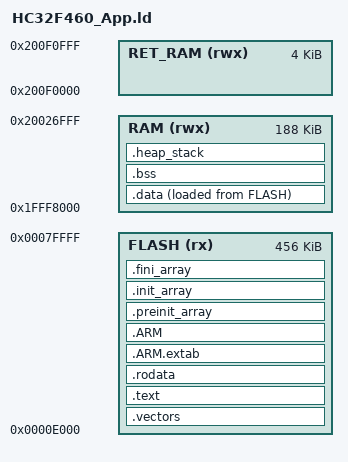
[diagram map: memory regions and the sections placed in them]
/******************************************************************************
 * HC32F460 App Linker Script
 *
 * The App runs from 0x0000E000 (bootloader jump target).
 * Used together with the bootloader's HC32F460_Bootloader.ld.
 *****************************************************************************/

MEMORY
{
    FLASH       (rx): ORIGIN = 0x0000E000, LENGTH = 456K
    RAM        (rwx): ORIGIN = 0x1FFF8000, LENGTH = 188K
    RET_RAM    (rwx): ORIGIN = 0x200F0000, LENGTH = 4K
}

ENTRY(Reset_Handler)

SECTIONS
{
    .vectors :
    {
        . = ALIGN(4);
        KEEP(*(.vectors))
        . = ALIGN(4);
    } >FLASH

    .text :
    {
        . = ALIGN(4);
        *(.text)
        *(.text*)
        *(.glue_7)
        *(.glue_7t)
        *(.eh_frame)
        KEEP(*(.init))
        KEEP(*(.fini))
        . = ALIGN(4);
    } >FLASH

    .rodata :
    {
        . = ALIGN(4);
        *(.rodata)
        *(.rodata*)
        . = ALIGN(4);
    } >FLASH

    .ARM.extab :
    {
        *(.ARM.extab* .gnu.linkonce.armextab.*)
    } >FLASH

    .ARM :
    {
        __exidx_start = .;
        *(.ARM.exidx*)
        __exidx_end = .;
    } >FLASH

    .preinit_array :
    {
        PROVIDE_HIDDEN(__preinit_array_start = .);
        KEEP(*(.preinit_array*))
        PROVIDE_HIDDEN(__preinit_array_end = .);
    } >FLASH

    .init_array :
    {
        PROVIDE_HIDDEN(__init_array_start = .);
        KEEP(*(SORT(.init_array.*)))
        KEEP(*(.init_array*))
        PROVIDE_HIDDEN(__init_array_end = .);
    } >FLASH

    .fini_array :
    {
        PROVIDE_HIDDEN(__fini_array_start = .);
        KEEP(*(SORT(.fini_array.*)))
        KEEP(*(.fini_array*))
        PROVIDE_HIDDEN(__fini_array_end = .);
    } >FLASH

    _sidata = LOADADDR(.data);
    __etext = LOADADDR(.data);

    .data :
    {
        . = ALIGN(4);
        __data_start__ = .;
        *(vtable)
        *(.data)
        *(.data*)
        . = ALIGN(4);
        *(.ramfunc)
        *(.ramfunc*)
        . = ALIGN(4);
        __data_end__ = .;
    } >RAM AT >FLASH

    .bss (NOLOAD):
    {
        . = ALIGN(4);
        _sbss = .;
        __bss_start__ = _sbss;
        *(.bss)
        *(.bss*)
        *(COMMON)
        . = ALIGN(4);
        _ebss = .;
        __bss_end__ = _ebss;
        *(.noinit*)
    } >RAM

    /* retention RAM symbols (the app does not use them, but the startup file needs the symbols to exist) */
    __data_start_ret_ram__ = ORIGIN(RET_RAM);
    __data_end_ret_ram__   = ORIGIN(RET_RAM);
    __bss_start_ret_ram__  = ORIGIN(RET_RAM);
    __bss_end_ret_ram__    = ORIGIN(RET_RAM);
    __etext_ret_ram        = __etext;

    .heap_stack (COPY) :
    {
        . = ALIGN(8);
        __end__ = .;
        PROVIDE(end = .);
        PROVIDE(_end = .);
        *(.heap*)
        . = ALIGN(8);
        __HeapLimit = .;

        __StackLimit = .;
        *(.stack*)
        . = ALIGN(8);
        __StackTop = .;
    } >RAM

    /DISCARD/ :
    {
        libc.a (*)
        libm.a (*)
        libgcc.a (*)
    }

    .ARM.attributes 0 : { *(.ARM.attributes) }

    PROVIDE(_stack = __StackTop);
    __RamEnd = ORIGIN(RAM) + LENGTH(RAM);
    ASSERT(__StackTop <= __RamEnd, "region RAM overflowed with stack")
}
